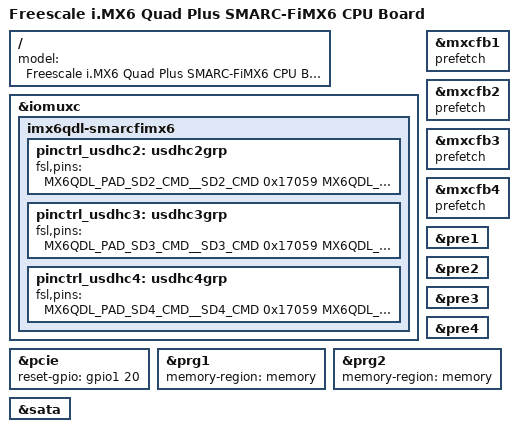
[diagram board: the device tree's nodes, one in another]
/*
 * Copyright (C) 2015 Freescale Semiconductor, Inc.
 *
 * This program is free software; you can redistribute it and/or modify
 * it under the terms of the GNU General Public License version 2 as
 * published by the Free Software Foundation.
 */

#include "imx6q-smarcfimx6.dts"
#include "imx6qp.dtsi"

/ {
	model = "Freescale i.MX6 Quad Plus SMARC-FiMX6 CPU Board";
};

&iomuxc {
	imx6qdl-smarcfimx6 {
                pinctrl_usdhc2: usdhc2grp {
                        fsl,pins = <
                                MX6QDL_PAD_SD2_CMD__SD2_CMD             0x17059
                                MX6QDL_PAD_SD2_CLK__SD2_CLK             0x10071
                                MX6QDL_PAD_SD2_DAT0__SD2_DATA0          0x17059
                                MX6QDL_PAD_SD2_DAT1__SD2_DATA1          0x17059
                                MX6QDL_PAD_SD2_DAT2__SD2_DATA2          0x17059
                                MX6QDL_PAD_SD2_DAT3__SD2_DATA3          0x17059
                        >;
                };

                pinctrl_usdhc3: usdhc3grp {
                        fsl,pins = <
                                MX6QDL_PAD_SD3_CMD__SD3_CMD             0x17059
                                MX6QDL_PAD_SD3_CLK__SD3_CLK             0x10071
                                MX6QDL_PAD_SD3_DAT0__SD3_DATA0          0x17059
                                MX6QDL_PAD_SD3_DAT1__SD3_DATA1          0x17059
                                MX6QDL_PAD_SD3_DAT2__SD3_DATA2          0x17059
                                MX6QDL_PAD_SD3_DAT3__SD3_DATA3          0x17059
                                MX6QDL_PAD_SD3_RST__SD3_RESET           0x17059
                        >;
                };

                pinctrl_usdhc4: usdhc4grp {
                        fsl,pins = <
                                MX6QDL_PAD_SD4_CMD__SD4_CMD             0x17059
                                MX6QDL_PAD_SD4_CLK__SD4_CLK             0x10071
                                MX6QDL_PAD_SD4_DAT0__SD4_DATA0          0x17059
                                MX6QDL_PAD_SD4_DAT1__SD4_DATA1          0x17059
                                MX6QDL_PAD_SD4_DAT2__SD4_DATA2          0x17059
                                MX6QDL_PAD_SD4_DAT3__SD4_DATA3          0x17059
                                MX6QDL_PAD_SD4_DAT4__SD4_DATA4          0x17059
                                MX6QDL_PAD_SD4_DAT5__SD4_DATA5          0x17059
                                MX6QDL_PAD_SD4_DAT6__SD4_DATA6          0x17059
                                MX6QDL_PAD_SD4_DAT7__SD4_DATA7          0x17059
                        >;
                };
	};
};

&mxcfb1 {
	prefetch;
};

&mxcfb2 {
	prefetch;
};

&mxcfb3 {
	prefetch;
};

&mxcfb4 {
	prefetch;
};

&pcie {
	reset-gpio = <&gpio1 20 0>;
	status = "okay";
};

&pre1 {
	status = "okay";
};

&pre2 {
	status = "okay";
};

&pre3 {
	status = "okay";
};

&pre4 {
	status = "okay";
};

&prg1 {
	memory-region = <&memory>;
	status = "okay";
};

&prg2 {
	memory-region = <&memory>;
	status = "okay";
};

&sata {
	status = "okay";
};
